# nrf54l10_application register map
Vendor: Nordic Semiconductor; Series: nrf54l; File version: 1
CPU: CM33 r0p4, little endian, MPU, FPU, 3 interrupt priority bits, 270 interrupts, 4 SAU regions
Registers are 32-bit, read-write, reset 0x0 unless marked. A register's access mark holds for its fields unless they carry their own. Offsets are from the block's base; [hi:lo] are bit positions; {n}, {i} and the like mark numbered series; 'fields as' and 'values as' point back to an identical list.

## GLOBAL_TAD_NS — Trace and debug control 0
Base 0x40053000; alternate view of GLOBAL_GPIOINTERNALP2_NS
Same registers: GLOBAL_TAD_S 0x50053000 (alternate view of GLOBAL_GPIOINTERNALP2_S)
0x400 SYSPWRUPREQ — System power-up request
  [0] ACTIVE — Activate power-up request
    0=NotActive (Power-up request not active); 1=Active (Power-up request active)
0x404 DBGPWRUPREQ — Debug power-up request
  fields as SYSPWRUPREQ
0x40C PDREQCLR — Clear the power request for SWD detection logic
  [0] PDREQCLR wo — Clear any false debugger connect status to allow system to use ELV voltage in System OFF
    1=Trigger operation
0x500 ENABLE — Enable debug domain and aquire selected GPIOs
  [0] ENABLE
    0=DISABLED (Disable debug domain and release selected GPIOs); 1=ENABLED (Enable debug domain and aquire selected GPIOs)
0x518 TRACEPORTSPEED
  [1:0] TRACEPORTSPEED — Trace port speed is divided from CPU clock. The TRACECLK pin output will be divided again by two from the trace port clock.
    0=DIV1 (Trace port speed equals CPU clock); 1=DIV2 (Trace port speed equals CPU clock divided by 2); 2=DIV4 (Trace port speed equals CPU clock divided by 4); 3=DIV32 (Trace port speed equals CPU clock divided by 32)
0x520 TINSTANCE — SW-DP Target instance
  [3:0] TINSTANCE — TINSTANCE bits are used in the SW-DP DLPIDR.TINSTANCE field.
0x600 DBGWAKEUPREQ reset 0x1 — Debug wakeup request configuration
  [2:0] TIMEOUT — Debug wakeup request timeout.
    0=Disabled (Timeout disabled); 1=Maximum (Timeout value is maximum, i.e., 0x400)

## GLOBAL_SREGS00_NS — Spare registers 0
Base 0x40056000
Same registers: GLOBAL_SREGS10_NS 0x4008C000, GLOBAL_SREGS20_NS 0x400E6000, GLOBAL_SREGS30_NS 0x4010F000, GLOBAL_SREGS00_S 0x50056000, GLOBAL_SREGS10_S 0x5008C000, GLOBAL_SREGS20_S 0x500E6000, GLOBAL_SREGS30_S 0x5010F000
{0x500+4i} REG[{i}] (i=0..1) — Description collection: Spare register n
  [31:0] VALUE
0x580 TESTREG — Test special register
  [3:0] TESTFIELD
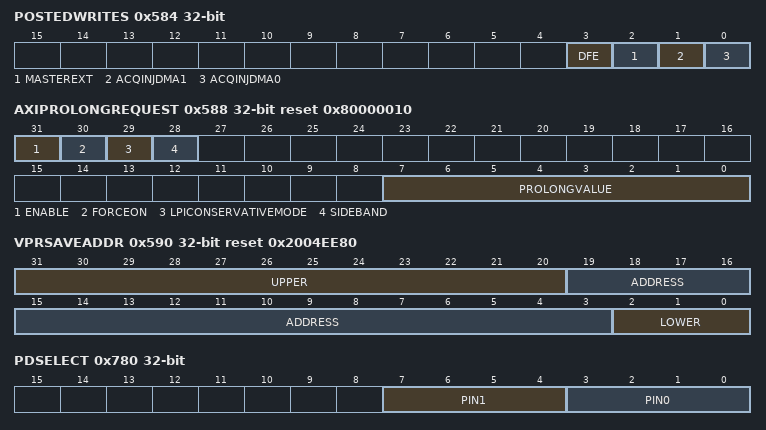
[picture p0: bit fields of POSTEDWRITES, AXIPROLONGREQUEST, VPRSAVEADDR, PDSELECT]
0x584 POSTEDWRITES — Enable or disable posted writes functionality for specific AXI/AHB bus masters
  [all] fields
    0=Disabled (Disable posted writes); 1=Enabled (Enable posted writes)
  [3] DFE — Disable or enable posted writes for Radio AHB for Direction Finding
  [2] MASTEREXT — Disable or enable posted writes for Radio AHB for Radio packets
  [1] ACQINJDMA1 — Disable or enable posted writes for Radio ACQINJDMA1
  [0] ACQINJDMA0 — Disable or enable posted writes for Radio ACQINJDMA0
0x588 AXIPROLONGREQUEST reset 0x80000010 — Configuration of the AxiRequestProlonger module.
  [31] ENABLE — Disable or enable the prolong functionality
    0=Disabled (Disable prolong functionality); 1=Enabled (Enable prolong functionality)
  [30] FORCEON — Disable or enable constant prolong request
    0=Disabled (Disable FORCEON); 1=Enabled (Enable FORCEON)
  [29] LPICONSERVATIVEMODE — Disable or enable LPI conservative mode
    values as the fields of POSTEDWRITES
  [28] SIDEBAND — Disable or enable additional sideband request
    0=Disabled (Disable sideband); 1=Enabled (Enable sideband)
  [7:0] PROLONGVALUE — Number of additional clocks the request is prolonged
0x58C RADIOSIDEBANDREQUEST — Sideband request from Radio to LRC.
  [0] SIDEBAND — Disable or enable sideband request for Radio
    0=Disabled (Disable sideband request); 1=Enabled (Enable sideband request)
0x590 VPRSAVEADDR reset 0x2004EE80 — VPR context save address.
  [31:20] UPPER ro — VPR context store address, upper range (static)
  [19:3] ADDRESS — VPR context store address
  [2:0] LOWER ro — VPR context store address, lower range (static)
{0x600+4i} MAINREG[{i}] (i=0..0) — Description collection: Spare register n in PD_MAIN
  [7:0] VALUE
{0x700+4i} AOREG[{i}] (i=0..0) — Description collection: Spare register n in PD_AO
  [3:0] VALUE
0x704 AODFT — AO control of DFT features
  [0] DTBENABLE — Output DTB on GPIO pins through Always-On pin muxing
0x780 PDSELECT — Power domain status selection
  [7:4] PIN1 — Mapping for pin P0.04
    0=Disable (pin is used as regular pin); 1=PdMain (Shows if PD_MAIN is on); 2=PdLp (Shows if PD_LP is on); 3=PdPeri (Shows if PD_M (also called PD_PERI) is on); 4=PdMcu (Shows if PD_MCU is on); 5=PdRadio (Shows if PD_RADIO is on); 6=PdCracen (Shows if PD_AUX (also called PD_CRACEN) is on); 7=PwrAboveElv (Not in Elv mode (pwrAboveElv_a)); 8=RequestPwrAboveElv (System request for ELV mode (requestPwrAboveElv_a)); 9=VregMainPwrupLdo (VREGMAIN (PwrDcdcLdo) power-up LDO signal); 10=VregMainPwrupPfm (VREGMAIN (PwrDcdcLdo) power-up PFM signal); 11=VregMainPwrupPwm (VREGMAIN (PwrDcdcLdo) power-up PWM signal)
  [3:0] PIN0 — Mapping for pin P0.03
    values as PIN1
